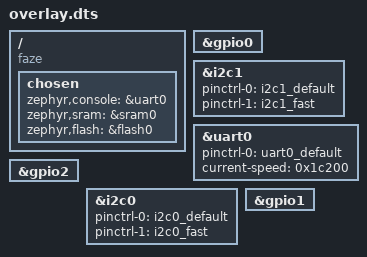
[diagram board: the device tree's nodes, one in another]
/ {
	compatible = "faze", "seagate,faze";
	chosen {
		zephyr,console = &uart0;
		zephyr,sram = &sram0;
		zephyr,flash = &flash0;
	};
};
&gpio0{
	status = "okay";
};
&i2c1{
	status = "okay";
	pinctrl-0 = < &i2c1_default >;
	pinctrl-1 = < &i2c1_fast >;
	pinctrl-names = "default", "fast-plus";
};
&uart0{
	status = "okay";
	pinctrl-0 = < &uart0_default >;
	pinctrl-names = "default";
	current-speed = < 0x1c200 >;
};
&gpio2{
	status = "okay";
};
&i2c0{
	status = "okay";
	pinctrl-0 = < &i2c0_default >;
	pinctrl-1 = < &i2c0_fast >;
	pinctrl-names = "default", "fast-plus";
};
&gpio1{
	status = "okay";
};
